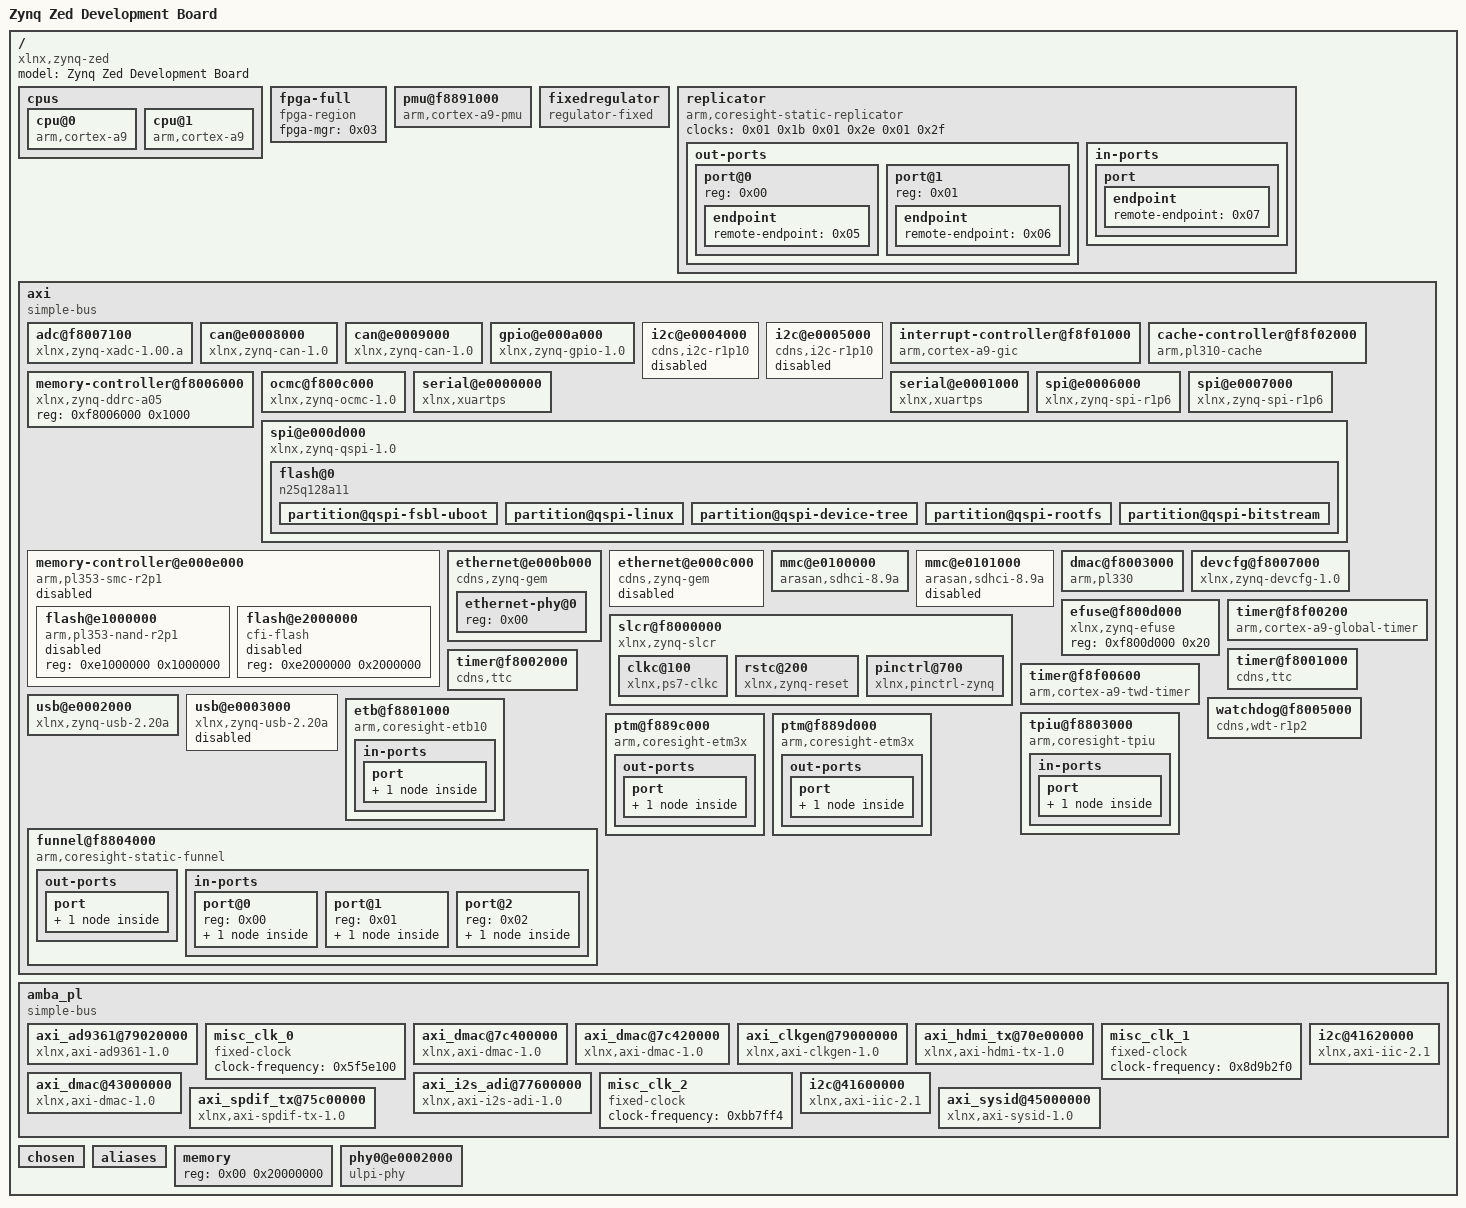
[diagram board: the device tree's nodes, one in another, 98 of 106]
/dts-v1/;

/ {
	#address-cells = <0x01>;
	#size-cells = <0x01>;
	compatible = "xlnx,zynq-zed\0xlnx,zynq-7000";
	model = "Zynq Zed Development Board";

	cpus {
		#address-cells = <0x01>;
		#size-cells = <0x00>;

		cpu@0 {
			compatible = "arm,cortex-a9";
			device_type = "cpu";
			reg = <0x00>;
			clocks = <0x01 0x03>;
			clock-latency = <0x3e8>;
			cpu0-supply = <0x02>;
			operating-points = <0xa2c2a 0xf4240 0x51615 0xf4240>;
			phandle = <0x10>;
		};

		cpu@1 {
			compatible = "arm,cortex-a9";
			device_type = "cpu";
			reg = <0x01>;
			clocks = <0x01 0x03>;
			phandle = <0x12>;
		};
	};

	fpga-full {
		compatible = "fpga-region";
		fpga-mgr = <0x03>;
		#address-cells = <0x01>;
		#size-cells = <0x01>;
		ranges;
		phandle = <0x17>;
	};

	pmu@f8891000 {
		compatible = "arm,cortex-a9-pmu";
		interrupts = <0x00 0x05 0x04 0x00 0x06 0x04>;
		interrupt-parent = <0x04>;
		reg = <0xf8891000 0x1000 0xf8893000 0x1000>;
	};

	fixedregulator {
		compatible = "regulator-fixed";
		regulator-name = "VCCPINT";
		regulator-min-microvolt = <0xf4240>;
		regulator-max-microvolt = <0xf4240>;
		regulator-boot-on;
		regulator-always-on;
		phandle = <0x02>;
	};

	replicator {
		compatible = "arm,coresight-static-replicator";
		clocks = <0x01 0x1b 0x01 0x2e 0x01 0x2f>;
		clock-names = "apb_pclk\0dbg_trc\0dbg_apb";

		out-ports {
			#address-cells = <0x01>;
			#size-cells = <0x00>;

			port@0 {
				reg = <0x00>;

				endpoint {
					remote-endpoint = <0x05>;
					phandle = <0x0c>;
				};
			};

			port@1 {
				reg = <0x01>;

				endpoint {
					remote-endpoint = <0x06>;
					phandle = <0x0b>;
				};
			};
		};

		in-ports {

			port {

				endpoint {
					remote-endpoint = <0x07>;
					phandle = <0x0d>;
				};
			};
		};
	};

	axi {
		u-boot,dm-pre-reloc;
		compatible = "simple-bus";
		#address-cells = <0x01>;
		#size-cells = <0x01>;
		interrupt-parent = <0x04>;
		ranges;
		phandle = <0x18>;

		adc@f8007100 {
			compatible = "xlnx,zynq-xadc-1.00.a";
			reg = <0xf8007100 0x20>;
			interrupts = <0x00 0x07 0x04>;
			interrupt-parent = <0x04>;
			clocks = <0x01 0x0c>;
			phandle = <0x19>;
		};

		can@e0008000 {
			compatible = "xlnx,zynq-can-1.0";
			status = "okay";
			clocks = <0x01 0x13 0x01 0x24>;
			clock-names = "can_clk\0pclk";
			reg = <0xe0008000 0x1000>;
			interrupts = <0x00 0x1c 0x04>;
			interrupt-parent = <0x04>;
			tx-fifo-depth = <0x40>;
			rx-fifo-depth = <0x40>;
			phandle = <0x1a>;
		};

		can@e0009000 {
			compatible = "xlnx,zynq-can-1.0";
			status = "okay";
			clocks = <0x01 0x14 0x01 0x25>;
			clock-names = "can_clk\0pclk";
			reg = <0xe0009000 0x1000>;
			interrupts = <0x00 0x33 0x04>;
			interrupt-parent = <0x04>;
			tx-fifo-depth = <0x40>;
			rx-fifo-depth = <0x40>;
			phandle = <0x1b>;
		};

		gpio@e000a000 {
			compatible = "xlnx,zynq-gpio-1.0";
			#gpio-cells = <0x02>;
			clocks = <0x01 0x2a>;
			gpio-controller;
			interrupt-controller;
			#interrupt-cells = <0x02>;
			interrupt-parent = <0x04>;
			interrupts = <0x00 0x14 0x04>;
			reg = <0xe000a000 0x1000>;
			emio-gpio-width = <0x40>;
			gpio-mask-high = <0x00>;
			gpio-mask-low = <0x5600>;
			phandle = <0x1c>;
		};

		i2c@e0004000 {
			compatible = "cdns,i2c-r1p10";
			status = "disabled";
			clocks = <0x01 0x26>;
			interrupt-parent = <0x04>;
			interrupts = <0x00 0x19 0x04>;
			reg = <0xe0004000 0x1000>;
			#address-cells = <0x01>;
			#size-cells = <0x00>;
			phandle = <0x1d>;
		};

		i2c@e0005000 {
			compatible = "cdns,i2c-r1p10";
			status = "disabled";
			clocks = <0x01 0x27>;
			interrupt-parent = <0x04>;
			interrupts = <0x00 0x30 0x04>;
			reg = <0xe0005000 0x1000>;
			#address-cells = <0x01>;
			#size-cells = <0x00>;
			phandle = <0x1e>;
		};

		interrupt-controller@f8f01000 {
			compatible = "arm,cortex-a9-gic";
			#interrupt-cells = <0x03>;
			interrupt-controller;
			reg = <0xf8f01000 0x1000 0xf8f00100 0x100>;
			num_cpus = <0x02>;
			num_interrupts = <0x60>;
			phandle = <0x04>;
		};

		cache-controller@f8f02000 {
			compatible = "arm,pl310-cache";
			reg = <0xf8f02000 0x1000>;
			interrupts = <0x00 0x02 0x04>;
			arm,data-latency = <0x03 0x02 0x02>;
			arm,tag-latency = <0x02 0x02 0x02>;
			cache-unified;
			cache-level = <0x02>;
			phandle = <0x1f>;
		};

		memory-controller@f8006000 {
			compatible = "xlnx,zynq-ddrc-a05";
			reg = <0xf8006000 0x1000>;
			phandle = <0x20>;
		};

		ocmc@f800c000 {
			compatible = "xlnx,zynq-ocmc-1.0";
			interrupt-parent = <0x04>;
			interrupts = <0x00 0x03 0x04>;
			reg = <0xf800c000 0x1000>;
			phandle = <0x21>;
		};

		serial@e0000000 {
			compatible = "xlnx,xuartps\0cdns,uart-r1p8";
			status = "okay";
			clocks = <0x01 0x17 0x01 0x28>;
			clock-names = "uart_clk\0pclk";
			reg = <0xe0000000 0x1000>;
			interrupts = <0x00 0x1b 0x04>;
			cts-override;
			device_type = "serial";
			port-number = <0x00>;
			phandle = <0x22>;
		};

		serial@e0001000 {
			compatible = "xlnx,xuartps\0cdns,uart-r1p8";
			status = "okay";
			clocks = <0x01 0x18 0x01 0x29>;
			clock-names = "uart_clk\0pclk";
			reg = <0xe0001000 0x1000>;
			interrupts = <0x00 0x32 0x04>;
			cts-override;
			device_type = "serial";
			port-number = <0x01>;
			u-boot,dm-pre-reloc;
			phandle = <0x23>;
		};

		spi@e0006000 {
			compatible = "xlnx,zynq-spi-r1p6";
			reg = <0xe0006000 0x1000>;
			status = "okay";
			interrupt-parent = <0x04>;
			interrupts = <0x00 0x1a 0x04>;
			clocks = <0x01 0x19 0x01 0x22>;
			clock-names = "ref_clk\0pclk";
			#address-cells = <0x01>;
			#size-cells = <0x00>;
			is-decoded-cs = <0x00>;
			num-cs = <0x03>;
			phandle = <0x24>;
		};

		spi@e0007000 {
			compatible = "xlnx,zynq-spi-r1p6";
			reg = <0xe0007000 0x1000>;
			status = "okay";
			interrupt-parent = <0x04>;
			interrupts = <0x00 0x31 0x04>;
			clocks = <0x01 0x1a 0x01 0x23>;
			clock-names = "ref_clk\0pclk";
			#address-cells = <0x01>;
			#size-cells = <0x00>;
			is-decoded-cs = <0x00>;
			num-cs = <0x03>;
			phandle = <0x25>;
		};

		spi@e000d000 {
			clock-names = "ref_clk\0pclk";
			clocks = <0x01 0x0a 0x01 0x2b>;
			compatible = "xlnx,zynq-qspi-1.0";
			status = "okay";
			interrupt-parent = <0x04>;
			interrupts = <0x00 0x13 0x04>;
			reg = <0xe000d000 0x1000>;
			#address-cells = <0x01>;
			#size-cells = <0x00>;
			is-dual = <0x00>;
			num-cs = <0x01>;
			spi-rx-bus-width = <0x04>;
			spi-tx-bus-width = <0x04>;
			u-boot,dm-pre-reloc;
			phandle = <0x26>;

			flash@0 {
				compatible = "n25q128a11\0jedec,spi-nor";
				reg = <0x00>;
				spi-tx-bus-width = <0x01>;
				spi-rx-bus-width = <0x04>;
				spi-max-frequency = <0x2faf080>;
				#address-cells = <0x01>;
				#size-cells = <0x01>;

				partition@qspi-fsbl-uboot {
					label = "qspi-fsbl-uboot";
					reg = <0x00 0x100000>;
				};

				partition@qspi-linux {
					label = "qspi-linux";
					reg = <0x100000 0x500000>;
				};

				partition@qspi-device-tree {
					label = "qspi-device-tree";
					reg = <0x600000 0x20000>;
				};

				partition@qspi-rootfs {
					label = "qspi-rootfs";
					reg = <0x620000 0x5e0000>;
				};

				partition@qspi-bitstream {
					label = "qspi-bitstream";
					reg = <0xc00000 0x400000>;
				};
			};
		};

		memory-controller@e000e000 {
			#address-cells = <0x01>;
			#size-cells = <0x01>;
			status = "disabled";
			clock-names = "memclk\0apb_pclk";
			clocks = <0x01 0x0b 0x01 0x2c>;
			compatible = "arm,pl353-smc-r2p1\0arm,primecell";
			interrupt-parent = <0x04>;
			interrupts = <0x00 0x12 0x04>;
			ranges;
			reg = <0xe000e000 0x1000>;
			phandle = <0x27>;

			flash@e1000000 {
				status = "disabled";
				compatible = "arm,pl353-nand-r2p1";
				reg = <0xe1000000 0x1000000>;
				#address-cells = <0x01>;
				#size-cells = <0x01>;
				phandle = <0x28>;
			};

			flash@e2000000 {
				status = "disabled";
				compatible = "cfi-flash";
				reg = <0xe2000000 0x2000000>;
				#address-cells = <0x01>;
				#size-cells = <0x01>;
				phandle = <0x29>;
			};
		};

		ethernet@e000b000 {
			compatible = "cdns,zynq-gem\0cdns,gem";
			reg = <0xe000b000 0x1000>;
			status = "okay";
			interrupts = <0x00 0x16 0x04>;
			clocks = <0x01 0x1e 0x01 0x1e 0x01 0x0d>;
			clock-names = "pclk\0hclk\0tx_clk";
			#address-cells = <0x01>;
			#size-cells = <0x00>;
			phy-mode = "rgmii-id";
			xlnx,ptp-enet-clock = <0x69f6bcb>;
			phy-handle = <0x08>;
			local-mac-address = [00 0a 35 00 00 55];
			phandle = <0x2a>;

			ethernet-phy@0 {
				reg = <0x00>;
				device_type = "ethernet-phy";
				phandle = <0x08>;
			};
		};

		ethernet@e000c000 {
			compatible = "cdns,zynq-gem\0cdns,gem";
			reg = <0xe000c000 0x1000>;
			status = "disabled";
			interrupts = <0x00 0x2d 0x04>;
			clocks = <0x01 0x1f 0x01 0x1f 0x01 0x0e>;
			clock-names = "pclk\0hclk\0tx_clk";
			#address-cells = <0x01>;
			#size-cells = <0x00>;
			phandle = <0x2b>;
		};

		mmc@e0100000 {
			compatible = "arasan,sdhci-8.9a";
			status = "okay";
			clock-names = "clk_xin\0clk_ahb";
			clocks = <0x01 0x15 0x01 0x20>;
			interrupt-parent = <0x04>;
			interrupts = <0x00 0x18 0x04>;
			reg = <0xe0100000 0x1000>;
			xlnx,has-cd = <0x01>;
			xlnx,has-power = <0x00>;
			xlnx,has-wp = <0x01>;
			u-boot,dm-pre-reloc;
			phandle = <0x2c>;
		};

		mmc@e0101000 {
			compatible = "arasan,sdhci-8.9a";
			status = "disabled";
			clock-names = "clk_xin\0clk_ahb";
			clocks = <0x01 0x16 0x01 0x21>;
			interrupt-parent = <0x04>;
			interrupts = <0x00 0x2f 0x04>;
			reg = <0xe0101000 0x1000>;
			phandle = <0x2d>;
		};

		slcr@f8000000 {
			u-boot,dm-pre-reloc;
			#address-cells = <0x01>;
			#size-cells = <0x01>;
			compatible = "xlnx,zynq-slcr\0syscon\0simple-mfd";
			reg = <0xf8000000 0x1000>;
			ranges;
			phandle = <0x09>;

			clkc@100 {
				u-boot,dm-pre-reloc;
				#clock-cells = <0x01>;
				compatible = "xlnx,ps7-clkc";
				fclk-enable = <0x03>;
				clock-output-names = "armpll\0ddrpll\0iopll\0cpu_6or4x\0cpu_3or2x\0cpu_2x\0cpu_1x\0ddr2x\0ddr3x\0dci\0lqspi\0smc\0pcap\0gem0\0gem1\0fclk0\0fclk1\0fclk2\0fclk3\0can0\0can1\0sdio0\0sdio1\0uart0\0uart1\0spi0\0spi1\0dma\0usb0_aper\0usb1_aper\0gem0_aper\0gem1_aper\0sdio0_aper\0sdio1_aper\0spi0_aper\0spi1_aper\0can0_aper\0can1_aper\0i2c0_aper\0i2c1_aper\0uart0_aper\0uart1_aper\0gpio_aper\0lqspi_aper\0smc_aper\0swdt\0dbg_trc\0dbg_apb";
				reg = <0x100 0x100>;
				ps-clk-frequency = <0x1fca055>;
				phandle = <0x01>;
			};

			rstc@200 {
				compatible = "xlnx,zynq-reset";
				reg = <0x200 0x48>;
				#reset-cells = <0x01>;
				syscon = <0x09>;
				phandle = <0x2e>;
			};

			pinctrl@700 {
				compatible = "xlnx,pinctrl-zynq";
				reg = <0x700 0x200>;
				syscon = <0x09>;
				phandle = <0x2f>;
			};
		};

		dmac@f8003000 {
			compatible = "arm,pl330\0arm,primecell";
			reg = <0xf8003000 0x1000>;
			interrupt-parent = <0x04>;
			interrupt-names = "abort\0dma0\0dma1\0dma2\0dma3\0dma4\0dma5\0dma6\0dma7";
			interrupts = <0x00 0x0d 0x04 0x00 0x0e 0x04 0x00 0x0f 0x04 0x00 0x10 0x04 0x00 0x11 0x04 0x00 0x28 0x04 0x00 0x29 0x04 0x00 0x2a 0x04 0x00 0x2b 0x04>;
			#dma-cells = <0x01>;
			#dma-channels = <0x08>;
			#dma-requests = <0x04>;
			clocks = <0x01 0x1b>;
			clock-names = "apb_pclk";
			phandle = <0x30>;
		};

		devcfg@f8007000 {
			compatible = "xlnx,zynq-devcfg-1.0";
			interrupt-parent = <0x04>;
			interrupts = <0x00 0x08 0x04>;
			reg = <0xf8007000 0x100>;
			clocks = <0x01 0x0c 0x01 0x0f 0x01 0x10 0x01 0x11 0x01 0x12>;
			clock-names = "ref_clk\0fclk0\0fclk1\0fclk2\0fclk3";
			syscon = <0x09>;
			phandle = <0x03>;
		};

		efuse@f800d000 {
			compatible = "xlnx,zynq-efuse";
			reg = <0xf800d000 0x20>;
			phandle = <0x31>;
		};

		timer@f8f00200 {
			compatible = "arm,cortex-a9-global-timer";
			reg = <0xf8f00200 0x20>;
			interrupts = <0x01 0x0b 0x301>;
			interrupt-parent = <0x04>;
			clocks = <0x01 0x04>;
			phandle = <0x32>;
		};

		timer@f8001000 {
			interrupt-parent = <0x04>;
			interrupts = <0x00 0x0a 0x04 0x00 0x0b 0x04 0x00 0x0c 0x04>;
			compatible = "cdns,ttc";
			clocks = <0x01 0x06>;
			reg = <0xf8001000 0x1000>;
			phandle = <0x33>;
		};

		timer@f8002000 {
			interrupt-parent = <0x04>;
			interrupts = <0x00 0x25 0x04 0x00 0x26 0x04 0x00 0x27 0x04>;
			compatible = "cdns,ttc";
			clocks = <0x01 0x06>;
			reg = <0xf8002000 0x1000>;
			phandle = <0x34>;
		};

		timer@f8f00600 {
			interrupt-parent = <0x04>;
			interrupts = <0x01 0x0d 0x301>;
			compatible = "arm,cortex-a9-twd-timer";
			reg = <0xf8f00600 0x20>;
			clocks = <0x01 0x04>;
			phandle = <0x35>;
		};

		usb@e0002000 {
			compatible = "xlnx,zynq-usb-2.20a\0chipidea,usb2";
			status = "okay";
			clocks = <0x01 0x1c>;
			interrupt-parent = <0x04>;
			interrupts = <0x00 0x15 0x04>;
			reg = <0xe0002000 0x1000>;
			phy_type = "ulpi";
			dr_mode = "host";
			usb-phy = <0x0a>;
			phandle = <0x36>;
		};

		usb@e0003000 {
			compatible = "xlnx,zynq-usb-2.20a\0chipidea,usb2";
			status = "disabled";
			clocks = <0x01 0x1d>;
			interrupt-parent = <0x04>;
			interrupts = <0x00 0x2c 0x04>;
			reg = <0xe0003000 0x1000>;
			phy_type = "ulpi";
			phandle = <0x37>;
		};

		watchdog@f8005000 {
			clocks = <0x01 0x2d>;
			compatible = "cdns,wdt-r1p2";
			interrupt-parent = <0x04>;
			interrupts = <0x00 0x09 0x01>;
			reg = <0xf8005000 0x1000>;
			timeout-sec = <0x0a>;
			phandle = <0x38>;
		};

		etb@f8801000 {
			compatible = "arm,coresight-etb10\0arm,primecell";
			reg = <0xf8801000 0x1000>;
			clocks = <0x01 0x1b 0x01 0x2e 0x01 0x2f>;
			clock-names = "apb_pclk\0dbg_trc\0dbg_apb";

			in-ports {

				port {

					endpoint {
						remote-endpoint = <0x0b>;
						phandle = <0x06>;
					};
				};
			};
		};

		tpiu@f8803000 {
			compatible = "arm,coresight-tpiu\0arm,primecell";
			reg = <0xf8803000 0x1000>;
			clocks = <0x01 0x1b 0x01 0x2e 0x01 0x2f>;
			clock-names = "apb_pclk\0dbg_trc\0dbg_apb";

			in-ports {

				port {

					endpoint {
						remote-endpoint = <0x0c>;
						phandle = <0x05>;
					};
				};
			};
		};

		funnel@f8804000 {
			compatible = "arm,coresight-static-funnel\0arm,primecell";
			reg = <0xf8804000 0x1000>;
			clocks = <0x01 0x1b 0x01 0x2e 0x01 0x2f>;
			clock-names = "apb_pclk\0dbg_trc\0dbg_apb";

			out-ports {

				port {

					endpoint {
						remote-endpoint = <0x0d>;
						phandle = <0x07>;
					};
				};
			};

			in-ports {
				#address-cells = <0x01>;
				#size-cells = <0x00>;

				port@0 {
					reg = <0x00>;

					endpoint {
						remote-endpoint = <0x0e>;
						phandle = <0x11>;
					};
				};

				port@1 {
					reg = <0x01>;

					endpoint {
						remote-endpoint = <0x0f>;
						phandle = <0x13>;
					};
				};

				port@2 {
					reg = <0x02>;

					endpoint {
						phandle = <0x39>;
					};
				};
			};
		};

		ptm@f889c000 {
			compatible = "arm,coresight-etm3x\0arm,primecell";
			reg = <0xf889c000 0x1000>;
			clocks = <0x01 0x1b 0x01 0x2e 0x01 0x2f>;
			clock-names = "apb_pclk\0dbg_trc\0dbg_apb";
			cpu = <0x10>;

			out-ports {

				port {

					endpoint {
						remote-endpoint = <0x11>;
						phandle = <0x0e>;
					};
				};
			};
		};

		ptm@f889d000 {
			compatible = "arm,coresight-etm3x\0arm,primecell";
			reg = <0xf889d000 0x1000>;
			clocks = <0x01 0x1b 0x01 0x2e 0x01 0x2f>;
			clock-names = "apb_pclk\0dbg_trc\0dbg_apb";
			cpu = <0x12>;

			out-ports {

				port {

					endpoint {
						remote-endpoint = <0x13>;
						phandle = <0x0f>;
					};
				};
			};
		};
	};

	amba_pl {
		#address-cells = <0x01>;
		#size-cells = <0x01>;
		compatible = "simple-bus";
		ranges;
		phandle = <0x3a>;

		axi_ad9361@79020000 {
			clock-names = "delay_clk\0clk\0s_axi_aclk";
			clocks = <0x01 0x10 0x14 0x01 0x0f>;
			compatible = "xlnx,axi-ad9361-1.0";
			reg = <0x79020000 0x10000>;
			phandle = <0x3b>;
		};

		misc_clk_0 {
			#clock-cells = <0x00>;
			clock-frequency = <0x5f5e100>;
			compatible = "fixed-clock";
			phandle = <0x14>;
		};

		axi_dmac@7c400000 {
			clock-names = "s_axi_aclk\0m_dest_axi_aclk\0fifo_wr_clk";
			clocks = <0x01 0x0f 0x01 0x0f 0x14>;
			compatible = "xlnx,axi-dmac-1.0";
			interrupt-names = "irq";
			interrupt-parent = <0x04>;
			interrupts = <0x00 0x1f 0x04>;
			reg = <0x7c400000 0x1000>;
			phandle = <0x3c>;
		};

		axi_dmac@7c420000 {
			clock-names = "s_axi_aclk\0m_src_axi_aclk\0m_axis_aclk";
			clocks = <0x01 0x0f 0x01 0x0f 0x14>;
			compatible = "xlnx,axi-dmac-1.0";
			interrupt-names = "irq";
			interrupt-parent = <0x04>;
			interrupts = <0x00 0x20 0x04>;
			reg = <0x7c420000 0x1000>;
			phandle = <0x3d>;
		};

		axi_clkgen@79000000 {
			clock-names = "clk\0s_axi_aclk";
			clocks = <0x01 0x10 0x01 0x0f>;
			compatible = "xlnx,axi-clkgen-1.0";
			reg = <0x79000000 0x10000>;
			phandle = <0x3e>;
		};

		axi_hdmi_tx@70e00000 {
			clock-names = "reference_clk\0vdma_clk\0s_axi_aclk";
			clocks = <0x15 0x01 0x0f 0x01 0x0f>;
			compatible = "xlnx,axi-hdmi-tx-1.0";
			reg = <0x70e00000 0x10000>;
			phandle = <0x3f>;
		};

		misc_clk_1 {
			#clock-cells = <0x00>;
			clock-frequency = <0x8d9b2f0>;
			compatible = "fixed-clock";
			phandle = <0x15>;
		};

		axi_dmac@43000000 {
			clock-names = "s_axi_aclk\0m_src_axi_aclk\0m_axis_aclk";
			clocks = <0x01 0x0f 0x01 0x0f 0x01 0x0f>;
			compatible = "xlnx,axi-dmac-1.0";
			interrupt-names = "irq";
			interrupt-parent = <0x04>;
			interrupts = <0x00 0x1d 0x04>;
			reg = <0x43000000 0x1000>;
			phandle = <0x40>;
		};

		axi_i2s_adi@77600000 {
			clock-names = "data_clk_i\0dma_req_tx_aclk\0dma_req_rx_aclk\0s_axi_aclk";
			clocks = <0x16 0x01 0x0f 0x01 0x0f 0x01 0x0f>;
			compatible = "xlnx,axi-i2s-adi-1.0";
			reg = <0x77600000 0x10000>;
			phandle = <0x41>;
		};

		misc_clk_2 {
			#clock-cells = <0x00>;
			clock-frequency = <0xbb7ff4>;
			compatible = "fixed-clock";
			phandle = <0x16>;
		};

		i2c@41620000 {
			#address-cells = <0x01>;
			#size-cells = <0x00>;
			clock-names = "s_axi_aclk";
			clocks = <0x01 0x0f>;
			compatible = "xlnx,axi-iic-2.1\0xlnx,xps-iic-2.00.a";
			interrupt-names = "iic2intc_irpt";
			interrupt-parent = <0x04>;
			interrupts = <0x00 0x21 0x04>;
			reg = <0x41620000 0x1000>;
			phandle = <0x42>;
		};

		i2c@41600000 {
			#address-cells = <0x01>;
			#size-cells = <0x00>;
			clock-names = "s_axi_aclk";
			clocks = <0x01 0x0f>;
			compatible = "xlnx,axi-iic-2.1\0xlnx,xps-iic-2.00.a";
			interrupt-names = "iic2intc_irpt";
			interrupt-parent = <0x04>;
			interrupts = <0x00 0x1e 0x04>;
			reg = <0x41600000 0x1000>;
			phandle = <0x43>;
		};

		axi_spdif_tx@75c00000 {
			clock-names = "spdif_data_clk\0s_axi_aclk\0dma_req_aclk";
			clocks = <0x16 0x01 0x0f 0x01 0x0f>;
			compatible = "xlnx,axi-spdif-tx-1.0";
			reg = <0x75c00000 0x10000>;
			phandle = <0x44>;
		};

		axi_sysid@45000000 {
			clock-names = "s_axi_aclk";
			clocks = <0x01 0x0f>;
			compatible = "xlnx,axi-sysid-1.0";
			reg = <0x45000000 0x10000>;
			phandle = <0x45>;
		};
	};

	chosen {
		bootargs = "earlycon console=ttyPS0,115200 clk_ignore_unused root=/dev/mmcblk0p2 rw rootwait cma=512M";
		stdout-path = "serial0:115200n8";
	};

	aliases {
		ethernet0 = "/axi/ethernet@e000b000";
		i2c0 = "/amba_pl/i2c@41620000";
		i2c1 = "/amba_pl/i2c@41600000";
		serial0 = "/axi/serial@e0000000";
		serial1 = "/axi/serial@e0001000";
		spi0 = "/axi/spi@e000d000";
		spi1 = "/axi/spi@e0006000";
		spi2 = "/axi/spi@e0007000";
	};

	memory {
		device_type = "memory";
		reg = <0x00 0x20000000>;
	};

	phy0@e0002000 {
		compatible = "ulpi-phy";
		#phy-cells = <0x00>;
		reg = <0xe0002000 0x1000>;
		view-port = <0x170>;
		drv-vbus;
		phandle = <0x0a>;
	};

	__symbols__ {
		cpu0 = "/cpus/cpu@0";
		cpu1 = "/cpus/cpu@1";
		fpga_full = "/fpga-full";
		regulator_vccpint = "/fixedregulator";
		replicator_out_port0 = "/replicator/out-ports/port@0/endpoint";
		replicator_out_port1 = "/replicator/out-ports/port@1/endpoint";
		replicator_in_port0 = "/replicator/in-ports/port/endpoint";
		amba = "/axi";
		adc = "/axi/adc@f8007100";
		can0 = "/axi/can@e0008000";
		can1 = "/axi/can@e0009000";
		gpio0 = "/axi/gpio@e000a000";
		i2c0 = "/axi/i2c@e0004000";
		i2c1 = "/axi/i2c@e0005000";
		intc = "/axi/interrupt-controller@f8f01000";
		L2 = "/axi/cache-controller@f8f02000";
		mc = "/axi/memory-controller@f8006000";
		ocmc = "/axi/ocmc@f800c000";
		uart0 = "/axi/serial@e0000000";
		uart1 = "/axi/serial@e0001000";
		spi0 = "/axi/spi@e0006000";
		spi1 = "/axi/spi@e0007000";
		qspi = "/axi/spi@e000d000";
		smcc = "/axi/memory-controller@e000e000";
		nand0 = "/axi/memory-controller@e000e000/flash@e1000000";
		nor0 = "/axi/memory-controller@e000e000/flash@e2000000";
		gem0 = "/axi/ethernet@e000b000";
		ethernet_phy = "/axi/ethernet@e000b000/ethernet-phy@0";
		gem1 = "/axi/ethernet@e000c000";
		sdhci0 = "/axi/mmc@e0100000";
		sdhci1 = "/axi/mmc@e0101000";
		slcr = "/axi/slcr@f8000000";
		clkc = "/axi/slcr@f8000000/clkc@100";
		rstc = "/axi/slcr@f8000000/rstc@200";
		pinctrl0 = "/axi/slcr@f8000000/pinctrl@700";
		dmac_s = "/axi/dmac@f8003000";
		devcfg = "/axi/devcfg@f8007000";
		efuse = "/axi/efuse@f800d000";
		global_timer = "/axi/timer@f8f00200";
		ttc0 = "/axi/timer@f8001000";
		ttc1 = "/axi/timer@f8002000";
		scutimer = "/axi/timer@f8f00600";
		usb0 = "/axi/usb@e0002000";
		usb1 = "/axi/usb@e0003000";
		watchdog0 = "/axi/watchdog@f8005000";
		etb_in_port = "/axi/etb@f8801000/in-ports/port/endpoint";
		tpiu_in_port = "/axi/tpiu@f8803000/in-ports/port/endpoint";
		funnel_out_port = "/axi/funnel@f8804000/out-ports/port/endpoint";
		funnel0_in_port0 = "/axi/funnel@f8804000/in-ports/port@0/endpoint";
		funnel0_in_port1 = "/axi/funnel@f8804000/in-ports/port@1/endpoint";
		funnel0_in_port2 = "/axi/funnel@f8804000/in-ports/port@2/endpoint";
		ptm0_out_port = "/axi/ptm@f889c000/out-ports/port/endpoint";
		ptm1_out_port = "/axi/ptm@f889d000/out-ports/port/endpoint";
		amba_pl = "/amba_pl";
		axi_ad9361 = "/amba_pl/axi_ad9361@79020000";
		misc_clk_0 = "/amba_pl/misc_clk_0";
		axi_ad9361_adc_dma = "/amba_pl/axi_dmac@7c400000";
		axi_ad9361_dac_dma = "/amba_pl/axi_dmac@7c420000";
		axi_hdmi_clkgen = "/amba_pl/axi_clkgen@79000000";
		axi_hdmi_core = "/amba_pl/axi_hdmi_tx@70e00000";
		misc_clk_1 = "/amba_pl/misc_clk_1";
		axi_hdmi_dma = "/amba_pl/axi_dmac@43000000";
		axi_i2s_adi = "/amba_pl/axi_i2s_adi@77600000";
		misc_clk_2 = "/amba_pl/misc_clk_2";
		axi_iic_fmc = "/amba_pl/i2c@41620000";
		axi_iic_main = "/amba_pl/i2c@41600000";
		axi_spdif_tx_core = "/amba_pl/axi_spdif_tx@75c00000";
		axi_sysid_0 = "/amba_pl/axi_sysid@45000000";
		usb_phy0 = "/phy0@e0002000";
	};
};
